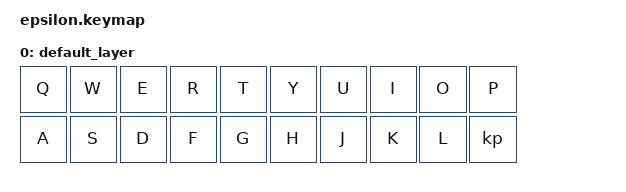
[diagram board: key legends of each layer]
/*
 * Copyright (c) 2020 The ZMK Contributors
 *
 * SPDX-License-Identifier: MIT
 */

#include <behaviors.dtsi>
#include <dt-bindings/zmk/keys.h>
#include <dt-bindings/zmk/bt.h>
#include <dt-bindings/zmk/mouse.h>


&mt {
    tapping-term-ms = <200>;
    flavor = "tap-preferred";
 };
&sk {
     release-after-ms = <2000>;
     quick-release;
 };


/ { 
    behaviors {
        hm: homerow_mods {
            compatible = "zmk,behavior-hold-tap";
            label = "HOMEROW_MODS";
            #binding-cells = <2>;
            tapping-term-ms = <200>;
            quick_tap_ms = <0>;
            flavor = "tap-preferred";
            bindings = <&kp>, <&kp>;
        };

	    td: tapdance {
            compatible = "zmk,behavior-hold-tap";
            label = "TAPDANCE";
            #binding-cells = <2>;
            tapping-term-ms = <190>;
            quick_tap_ms = <0>;
            flavor = "tap-preferred";
            bindings = <&kp>, <&kp>;
        };
    };

        keymap {
                compatible = "zmk,keymap";
                
       		default_layer {
		bindings = <
        &kp Q           &kp W           &kp E           &kp R           &kp T                       &kp Y           &kp U           &kp I           &kp O           &kp P
        &kp A           &kp S           &kp D           &kp F           &kp G                       &kp H           &kp J           &kp K           &kp L           &kp ;
        &kp Z           &kp X           &kp C           &kp V           &kp B                       &kp N           &kp M           &kp ,           &kp .           &kp /
                                        &kp E           &kp R           &kp T                       &kp Y           &kp U           &kp I           

		>;
		};

       	       
	};
};
